# netx90_app register map
File version: 1.0
CPU: CM4 r0p1, little endian, MPU, FPU, 4 interrupt priority bits, 78 interrupts
Registers are 32-bit, read-write, reset 0x0 unless marked. A register's access mark holds for its fields unless they carry their own. Offsets are from the block's base; [hi:lo] are bit positions; {n}, {i} and the like mark numbered series; 'fields as' and 'values as' point back to an identical list.

## gpio_xpic_app
Base 0xFF900200
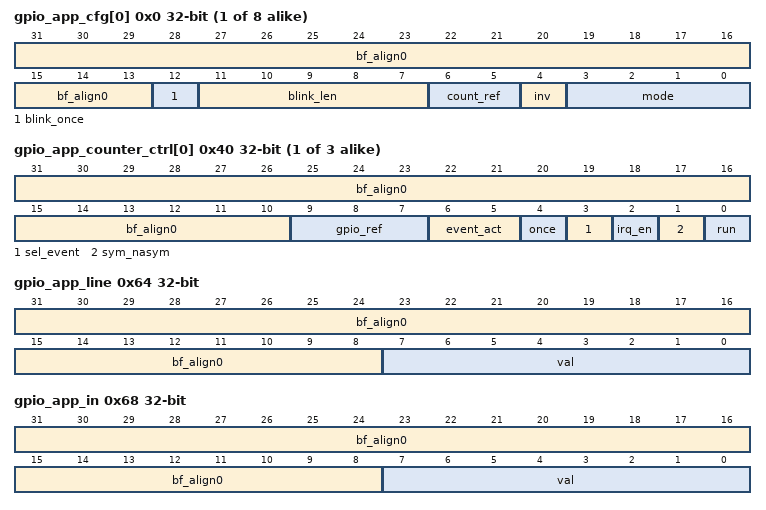
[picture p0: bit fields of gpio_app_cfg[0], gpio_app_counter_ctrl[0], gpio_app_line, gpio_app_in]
{0x0+4i} gpio_app_cfg[{i}] (i=0..7) (reset mask 0x1FFF) — GPIO_APP pin 0 config register: This register is accessible via address areas inlogic_app and xpic_app_system.
  [31:13] bf_align0 — bitField alignment value for aeabi compatibility
  [12] blink_once — Run blink sequence only once (blink mode only)
  [11:7] blink_len — Length of blink sequence minus 1 (blink mode only) 00000: use bit 0 of gpio_app_tc 00001: use bits 0..1 of gpio_app_tc 00010: use bits 0..2 of gpio_app_tc ... 11111: use bits 0..31 of gpio_app_tc
  [6:5] count_ref — counter reference 00: counter 0 01: counter 1 10: counter 2 11: sys_time (global system time)
  [4] inv — 1: invert input/output value 0: do not invert input/output
  [3:0] mode — defines the gp input or output mode - depends on io_cfg Input modes: 0000: read mode 0001: capture continued at rising edge (allows gpio_app_irq on each capture) 0010: capture once at rising edge (reset gpio_app_irq to capture again) 0011: capture once at high level (reset gpio_app_irq to capture again) Output modes: 0100: set to 0 0101: set to 1 0110: set to gpio_app_line[0] 0111: pwm mode, direct threshold update (might cause hazards on output) 1000: blink mode Multi pin modes: 1111: pwm2-mode with threshold update at counter=0 from gpio_app_tc[n+1] register (hazard-free)
{0x20+4i} gpio_app_tc[{i}] (i=0..7) — GPIO_APP pin 0 threshold or capture register: This register is accessible via address areas inlogic_app and xpic_app_system.
  [31:0] val — Threshold/Capture register: PWM mode (threshold): { | The counter threshold value equals the number of inactive clock cycles per period (cycles with pwm=0). Therefore it is interpreted differently in symmetrical and asymmetrical counter mode: Asymmetrical mode (sawtooth): pwm = (counter >= gpio_app_tc) Symmetrical mode (triangle) : Counter is compared with gpio_app_tc[31:1], gpio_app_tc[0] extends the inactive phase by 1 clock cycle only while counting up. This allows running a 10 ns resolution even in symmetrical mode.} Capture mode (capture register) { | In the capture mode, this register holds the captured counter value.} Blink mode (blink sequence) { | In the blink mode, this register holds the blinking sequence starting from bit 0.}
{0x40+4i} gpio_app_counter_ctrl[{i}] (i=0..2) (reset mask 0x3FF) — GPIO_APP counter0 control register: This register is accessible via address areas inlogic_app and xpic_app_system.
  [31:10] bf_align0 — bitField alignment value for aeabi compatibility
  [9:7] gpio_ref — gpio reference (0 - 7)
  [6:5] event_act — Define action of selected external event (dependent on sel_event, gpio_ref) 00: count every clock cycle, ignore external events 01: count only external events (edge or level according to bit sel_event) 10: enable watchdog mode of counter (external event will be reset without IRQ, overflow generates IRQ). 11: enable automatic run mode (external event sets run bit, used for DC-DC PWM in combination with bit once=1)
  [4] once — 1: count once (reset run bit after 1 period) 0: count continuously
  [3] sel_event — select external event 0: high level, invert gpio in register gpio_app_cfg to select low level 1: pos. edge, invert gpio in register gpio_app_cfg to select neg. edge
  [2] irq_en — 1: enable interrupt request on sel_event 0: disable interrupt request
  [1] sym_nasym — 1: symmetric mode (triangle) 0: asymmetric mode (sawtooth)
  [0] run — 1: start counter, counter is running 0: stop counter
{0x4C+4i} gpio_app_counter_max[{i}] (i=0..2) — GPIO_APP counter0 max value: This register is accessible via address areas inlogic_app and xpic_app_system.
  [31:0] val — Asymmetric mode: Counting period in cc + 1 Symmetric mode: Counting period in cc
{0x58+4i} gpio_app_counter_cnt[{i}] (i=0..2) — GPIO_APP counter0 current value: This register is accessible via address areas inlogic_app and xpic_app_system.
  [31:0] val — current counter value
0x64 gpio_app_line (reset mask 0xFF) — GPIO_APP line register This register is accessible via address areas inlogic_app and xpic_app_system.
  [31:8] bf_align0 — bitField alignment value for aeabi compatibility
  [7:0] val — gpio_app output values
0x68 gpio_app_in ro (reset mask 0xFF) — GPIO_APP latched inputs register: This register is accessible via address areas inlogic_app and xpic_app_system.
  [31:8] bf_align0 — bitField alignment value for aeabi compatibility
  [7:0] val — gpio_app input values
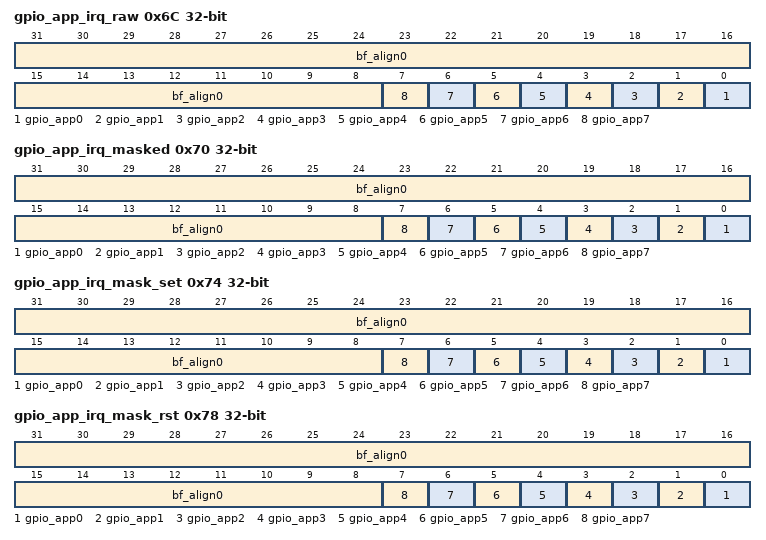
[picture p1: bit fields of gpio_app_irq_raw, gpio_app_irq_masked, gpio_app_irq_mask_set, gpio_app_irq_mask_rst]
0x6C gpio_app_irq_raw (reset mask 0xFF) — GPIO_APP raw IRQ register: Read access shows the status of unmasked IRQs. IRQs are set automatically and reset by writing to this register: Write access with '1' resets the corresponding IRQ. Write access with '0' does not influence this bit. This register is accessible via address areas inlogic_app and xpic_app_system.
  [31:8] bf_align0 — bitField alignment value for aeabi compatibility
  [n] gpio_app{n} (n=0..7) — Interrupt bit for GPIO_APP{n}
0x70 gpio_app_irq_masked ro (reset mask 0xFF) — GPIO_APP masked IRQ register: This register exists 2x for the different system busses (address areas) it is connected to. This allows 2 CPUs to work in parallel on this module: ARM_APP, xPIC_APP.
  fields as gpio_app_irq_raw
0x74 gpio_app_irq_mask_set (reset mask 0xFF) — GPIO_APP interrupt mask set: The interrupt mask register exists 2x for the different system busses (address areas) it is connected to. This allows 2 CPUs to work in parallel on this module: ARM_APP, xPIC_APP. The inlogic_app IRQ mask enables interrupt requests for ARM_APP. The xpic_app_system IRQ mask enables interrupt requests for xPIC_APP. Since different software tasks might change its bits, the IRQ mask register is not writable directly, but by set and reset masks: Write access with '1' sets the interrupt mask bit (enables the interrupt request for the corresponding interrupt source). Write access with '0' does not influence this bit. Read access shows the current interrupt mask. Note: Before activating the interrupt mask, delete old pending interrupts by writing the same value to gpio_app_irq_raw.
  fields as gpio_app_irq_raw
0x78 gpio_app_irq_mask_rst (reset mask 0xFF) — GPIO_APP interrupt mask reset: This reset mask serves to disable the interrupt requests for the corresponding interrupt sources. Like irq_msk_set, this address exists for the following address areas: inlogic_app, xpic_app_system. Write access with '1' resets the interrupt mask bit (disables the interrupt request for the corresponding interrupt source). Write access with '0' does not influence this bit. Read access shows the current interrupt mask.
  fields as gpio_app_irq_raw
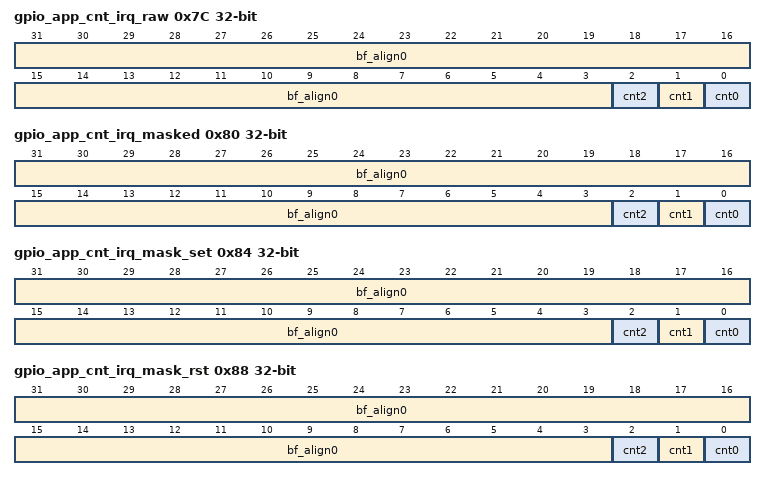
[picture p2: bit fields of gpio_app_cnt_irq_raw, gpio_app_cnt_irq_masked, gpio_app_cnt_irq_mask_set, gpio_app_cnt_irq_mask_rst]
0x7C gpio_app_cnt_irq_raw (reset mask 0x7) — Counter raw IRQ register: Read access shows the status of unmasked IRQs. IRQs are set automatically and reset by writing to this register: Write access with '1' resets the corresponding IRQ. Write access with '0' does not influence this bit. This register is accessible via address areas inlogic_app and xpic_app_system.
  [31:3] bf_align0 — bitField alignment value for aeabi compatibility
  [2] cnt2 — Interrupt bit for counter2
  [1] cnt1 — Interrupt bit for counter1
  [0] cnt0 — Interrupt bit for counter0
0x80 gpio_app_cnt_irq_masked ro (reset mask 0x7) — Counter masked IRQ register: Read access shows the status of masked IRQs (cnt_irq_raw AND cnt_irq_mask). This register exists 2x for the different system busses (address areas) it is connected to. This allows 2 CPUs to work in parallel on this module: ARM_APP, xPIC_APP.
  fields as gpio_app_cnt_irq_raw
0x84 gpio_app_cnt_irq_mask_set (reset mask 0x7) — Counter interrupt mask set: The interrupt mask register exists 2x for the different system busses (address areas) it is connected to. This allows 2 CPUs to work in parallel on this module: ARM_APP, xPIC_APP. The inlogic_app IRQ mask enables interrupt requests for ARM_APP. The xpic_app_system IRQ mask enables interrupt requests for xPIC_APP. Since different software tasks might change its bits, the IRQ mask register is not writable directly, but by set and reset masks: Write access with '1' sets the interrupt mask bit (enables the interrupt request for the corresponding interrupt source). Write access with '0' does not influence this bit. Read access shows the current interrupt mask. Note: Before activating the interrupt mask, delete old pending interrupts by writing the same value to cnt_irq_raw.
  fields as gpio_app_cnt_irq_raw
0x88 gpio_app_cnt_irq_mask_rst (reset mask 0x7) — Counter interrupt mask reset: This reset mask serves to disable the interrupt requests for the corresponding interrupt sources. Like cnt_irq_msk_set, this address exists for the following address areas: inlogic_app, xpic_app_system. Write access with '1' resets the interrupt mask bit (disables the interrupt request for the corresponding interrupt source). Write access with '0' does not influence this bit. Read access shows the current interrupt mask.
  fields as gpio_app_cnt_irq_raw
